# f28004x_cpu_sys_regs register map
Vendor: Texas Instruments
Peripheral module from a debugger description file (folder C2000).
Address unit: 16 bits
Registers are 32-bit, read-write, no defined reset value unless marked. A register's access mark holds for its fields unless they carry their own. Offsets are as the file gives them; lines under a group give offsets from that group; [hi:lo] are bit positions; {n}, {i} and the like mark numbered series; 'fields as' and 'values as' point back to an identical list; <NAME> marks a mode.

## CPU_SYS_REGS — CPU SYS Registers
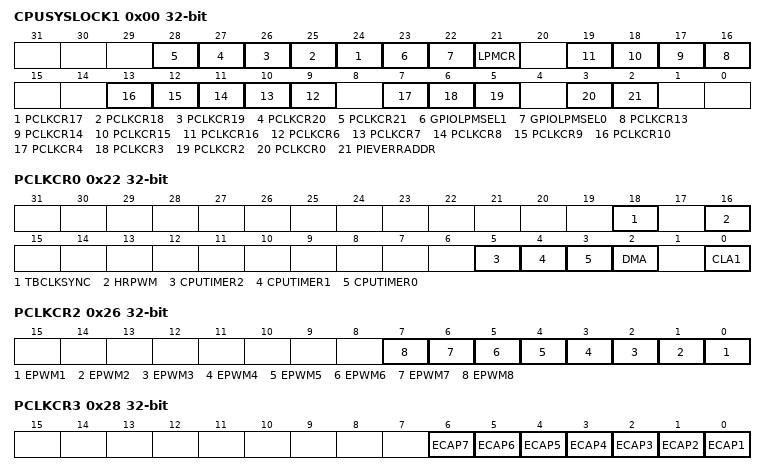
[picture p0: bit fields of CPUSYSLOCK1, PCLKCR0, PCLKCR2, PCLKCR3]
0x00 CPUSYSLOCK1 access not given — Lock bit for CPUSYS registers
  [n+7] PCLKCR{n} (n=17..21) — Lock bit for PCLKCR{n} Register (access R/SOnce)
  [23] GPIOLPMSEL1 — Lock bit for GPIOLPMSEL1 Register (access R/SOnce)
  [22] GPIOLPMSEL0 — Lock bit for GPIOLPMSEL0 Register (access R/SOnce)
  [21] LPMCR — Lock bit for LPMCR Register (access R/SOnce)
  [n+3] PCLKCR{n} (n=13..16) — Lock bit for PCLKCR{n} Register (access R/SOnce)
  [n+3] PCLKCR{n} (n=6..10) — Lock bit for PCLKCR{n} Register (access R/SOnce)
  [7] PCLKCR4 — Lock bit for PCLKCR4 Register (access R/SOnce)
  [6] PCLKCR3 — Lock bit for PCLKCR3 Register (access R/SOnce)
  [5] PCLKCR2 — Lock bit for PCLKCR2 Register (access R/SOnce)
  [3] PCLKCR0 — Lock bit for PCLKCR0 Register (access R/SOnce)
  [2] PIEVERRADDR — Lock bit for PIEVERRADDR Register (access R/SOnce)
0x0A PIEVERRADDR — PIE Vector Fetch Error Address register
  [21:0] ADDR — PIE Vector Fetch Error Handler Routine Address
0x22 PCLKCR0 — Peripheral Clock Gating Registers
  [18] TBCLKSYNC — EPWM Time Base Clock sync
  [16] HRPWM — HRPWM Clock Enable Bit
  [5] CPUTIMER2 — CPUTIMER2 Clock Enable bit
  [4] CPUTIMER1 — CPUTIMER1 Clock Enable bit
  [3] CPUTIMER0 — CPUTIMER0 Clock Enable bit
  [2] DMA — DMA Clock Enable bit
  [0] CLA1 — CLA1 Clock Enable Bit
0x26 PCLKCR2 — Peripheral Clock Gating Registers
  [n-1] EPWM{n} (n=1..8) — EPWM{n} Clock Enable bit
0x28 PCLKCR3 — Peripheral Clock Gating Registers
  [n-1] ECAP{n} (n=1..7) — ECAP{n} Clock Enable bit
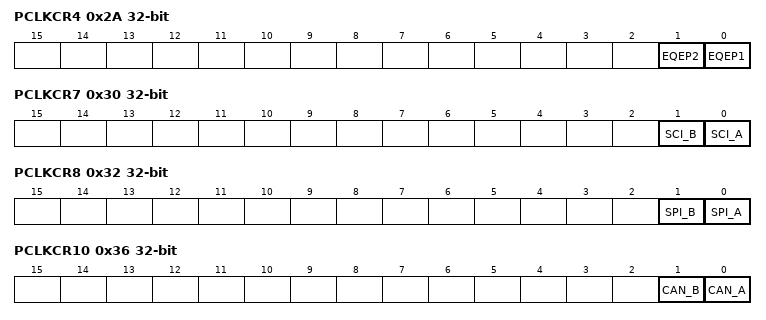
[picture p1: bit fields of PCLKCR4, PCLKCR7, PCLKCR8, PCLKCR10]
0x2A PCLKCR4 — Peripheral Clock Gating Registers
  [1] EQEP2 — EQEP2 Clock Enable bit
  [0] EQEP1 — EQEP1 Clock Enable bit
0x2E PCLKCR6 — Peripheral Clock Gating Registers
  [0] SD1 — SD1 Clock Enable bit
0x30 PCLKCR7 — Peripheral Clock Gating Registers
  [1] SCI_B — SCI_B Clock Enable bit
  [0] SCI_A — SCI_A Clock Enable bit
0x32 PCLKCR8 — Peripheral Clock Gating Registers
  [1] SPI_B — SPI_B Clock Enable bit
  [0] SPI_A — SPI_A Clock Enable bit
0x34 PCLKCR9 — Peripheral Clock Gating Registers
  [0] I2C_A — I2C_A Clock Enable bit
0x36 PCLKCR10 — Peripheral Clock Gating Registers
  [1] CAN_B — CAN_B Clock Enable bit
  [0] CAN_A — CAN_A Clock Enable bit
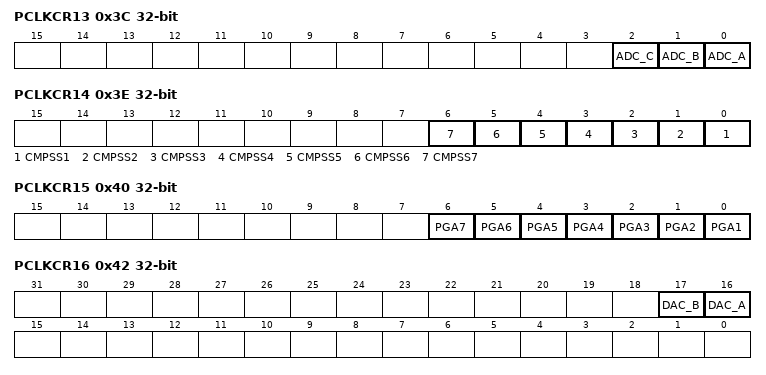
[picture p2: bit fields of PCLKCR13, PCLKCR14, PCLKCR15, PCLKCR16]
0x3C PCLKCR13 — Peripheral Clock Gating Registers
  [2] ADC_C — ADC_C Clock Enable bit
  [1] ADC_B — ADC_B Clock Enable bit
  [0] ADC_A — ADC_A Clock Enable bit
0x3E PCLKCR14 — Peripheral Clock Gating Registers
  [n-1] CMPSS{n} (n=1..7) — CMPSS{n} Clock Enable bit
0x40 PCLKCR15 — Peripheral Clock Gating Registers
  [n-1] PGA{n} (n=1..7) — PGA{n} Clock Enable bit
0x42 PCLKCR16 — Peripheral Clock Gating Registers
  [17] DAC_B — Buffered_DAC_B Clock Enable Bit
  [16] DAC_A — Buffered_DAC_A Clock Enable Bit
0x44 PCLKCR17 access not given — Peripheral Clock Gating Registers
0x46 PCLKCR18 access not given — Peripheral Clock Gating Registers
0x48 PCLKCR19 — Peripheral Clock Gating Registers
  [0] LIN_A — LIN_A Clock Enable bit
0x4A PCLKCR20 — Peripheral Clock Gating Registers
  [0] PMBUS_A — PMBUS_A Clock Enable bit
0x4C PCLKCR21 — Peripheral Clock Gating Registers
  [0] DCC_0 — DCC_0 Clock Enable Bit
0x76 LPMCR — LPM Control Register
  [1:0] LPM — Low Power Mode setting
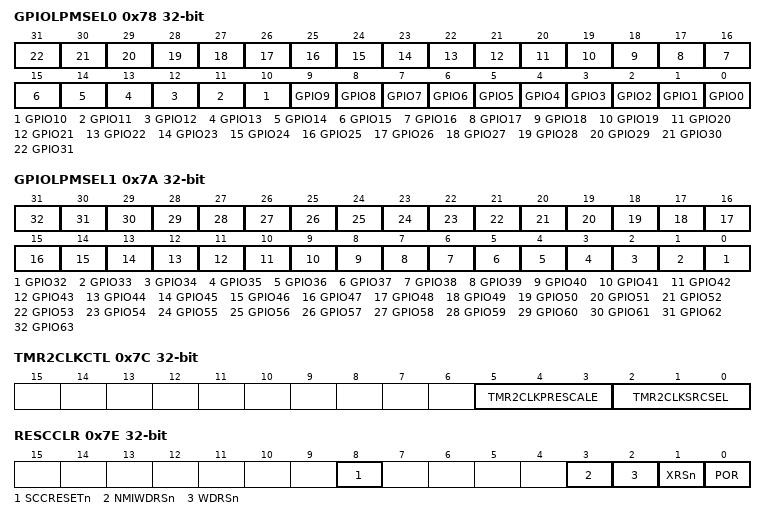
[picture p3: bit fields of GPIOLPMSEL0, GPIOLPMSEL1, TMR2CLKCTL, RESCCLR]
0x78 GPIOLPMSEL0 — GPIO LPM Wakeup select registers
  [n] GPIO{n} (n=0..31) — GPIO{n} Enable for LPM Wakeup
0x7A GPIOLPMSEL1 — GPIO LPM Wakeup select registers
  [n-32] GPIO{n} (n=32..63) — GPIO{n} Enable for LPM Wakeup
0x7C TMR2CLKCTL — Timer2 Clock Measurement functionality control register
  [5:3] TMR2CLKPRESCALE — CPU Timer 2 Clock Pre-Scale Value
  [2:0] TMR2CLKSRCSEL — CPU Timer 2 Clock Source Select Bit
0x7E RESCCLR access not given — Reset Cause Clear Register
  [8] SCCRESETn — SCCRESETn Reset Cause Indication Bit (access W=1)
  [3] NMIWDRSn — NMIWDRSn Reset Cause Indication Bit (access W=1)
  [2] WDRSn — WDRSn Reset Cause Indication Bit (access W=1)
  [1] XRSn — XRSn Reset Cause Indication Bit (access W=1)
  [0] POR — POR Reset Cause Indication Bit (access W=1)
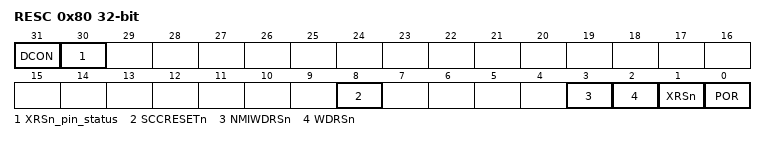
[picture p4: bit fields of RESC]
0x80 RESC ro — Reset Cause register
  [31] DCON — Debugger conntion status to C28x
  [30] XRSn_pin_status
  [8] SCCRESETn — SCCRESETn Reset Cause Indication Bit
  [3] NMIWDRSn — NMIWDRSn Reset Cause Indication Bit
  [2] WDRSn — WDRSn Reset Cause Indication Bit
  [1] XRSn — XRSn Reset Cause Indication Bit
  [0] POR — POR Reset Cause Indication Bit
